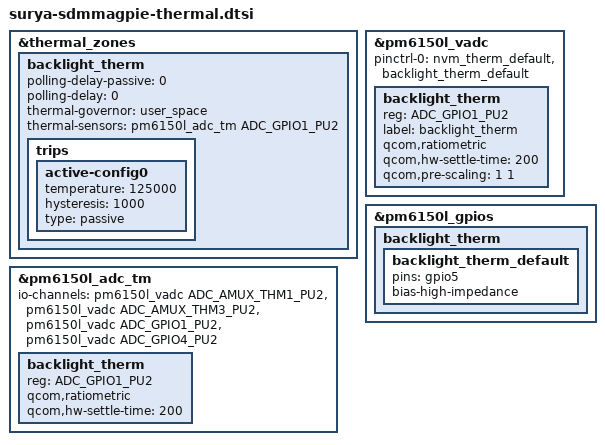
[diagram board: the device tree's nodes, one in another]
&thermal_zones {
	backlight_therm {
		polling-delay-passive = <0>;
		polling-delay = <0>;
		thermal-governor = "user_space";
		thermal-sensors = <&pm6150l_adc_tm ADC_GPIO1_PU2>;
		trips {
			active-config0 {
				temperature = <125000>;
				hysteresis = <1000>;
				type = "passive";
			};
		};
	};
};

&pm6150l_vadc {
	pinctrl-0 = <&nvm_therm_default>, <&backlight_therm_default>;

	backlight_therm {
		reg = <ADC_GPIO1_PU2>;
		label = "backlight_therm";
		qcom,ratiometric;
		qcom,hw-settle-time = <200>;
		qcom,pre-scaling = <1 1>;
	};

};

&pm6150l_gpios {
	backlight_therm {
		backlight_therm_default: backlight_therm_default {
			pins = "gpio5";
			bias-high-impedance;
		};
	};
};

&pm6150l_adc_tm {
	io-channels = <&pm6150l_vadc ADC_AMUX_THM1_PU2>,
			<&pm6150l_vadc ADC_AMUX_THM3_PU2>,
			<&pm6150l_vadc ADC_GPIO1_PU2>,
			<&pm6150l_vadc ADC_GPIO4_PU2>;

	backlight_therm {
		reg = <ADC_GPIO1_PU2>;
		qcom,ratiometric;
		qcom,hw-settle-time = <200>;
	};
};
